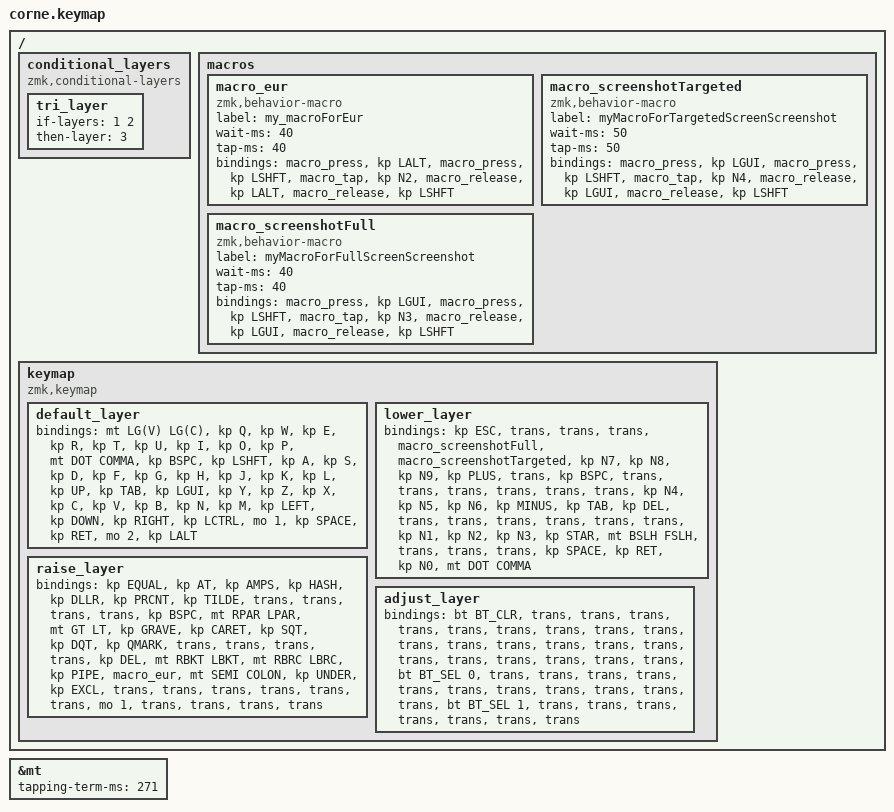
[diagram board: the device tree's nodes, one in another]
/*
 * Copyright (c) 2020 The ZMK Contributors
 *
 * SPDX-License-Identifier: MIT
 */

#include <behaviors.dtsi>
#include <dt-bindings/zmk/keys.h>
#include <dt-bindings/zmk/bt.h>


&mt {
    tapping-term-ms = <271>;
};


/ {

conditional_layers {
        compatible = "zmk,conditional-layers";
        tri_layer {
            if-layers = <1 2>;
            then-layer = <3>;
        };
  };


  macros {
    macro_eur: macro_eur {
        label = "my_macroForEur";
        compatible = "zmk,behavior-macro";
        #binding-cells = <0>;
        wait-ms = <40>;
        tap-ms = <40>;
        bindings
        = <&macro_press   &kp LALT>
        , <&macro_press   &kp LSHFT>    
        , <&macro_tap     &kp N2>
        , <&macro_release &kp LALT>
        , <&macro_release &kp LSHFT>
        ;
    };

  macro_screenshotTargeted: macro_screenshotTargeted {
        label = "myMacroForTargetedScreenScreenshot";
        compatible = "zmk,behavior-macro";
        #binding-cells = <0>;
        wait-ms = <50>;
        tap-ms = <50>;
        bindings
        = <&macro_press   &kp LGUI>
        , <&macro_press   &kp LSHFT>
        , <&macro_tap     &kp N4>
        , <&macro_release &kp LGUI>
        , <&macro_release &kp LSHFT>
        ;
    };


  macro_screenshotFull: macro_screenshotFull {
        label = "myMacroForFullScreenScreenshot";
        compatible = "zmk,behavior-macro";
        #binding-cells = <0>;
        wait-ms = <40>;
        tap-ms = <40>;
        bindings
        = <&macro_press   &kp LGUI>
        , <&macro_press   &kp LSHFT>
        , <&macro_tap     &kp N3>
        , <&macro_release &kp LGUI>
        , <&macro_release &kp LSHFT>
        ;
    };
};



        keymap {
                compatible = "zmk,keymap";

                default_layer {
 bindings = <
&mt LG(V) LG(C) &kp Q &kp W &kp E &kp R &kp T &kp U &kp I &kp O &kp P &mt DOT COMMA &kp BSPC &kp LSHFT &kp A &kp S &kp D &kp F &kp G &kp H &kp J &kp K &kp L &kp UP &kp TAB &kp LGUI &kp Y &kp Z &kp X &kp C &kp V &kp B &kp N &kp M &kp LEFT &kp DOWN &kp RIGHT &kp LCTRL &mo 1 &kp SPACE &kp RET &mo 2 &kp LALT
>;
                };
                lower_layer {

                        bindings = <
&kp ESC &trans &trans &trans &macro_screenshotFull &macro_screenshotTargeted &kp N7 &kp N8 &kp N9 &kp PLUS &trans &kp BSPC &trans &trans &trans &trans &trans &trans &kp N4 &kp N5 &kp N6 &kp MINUS &kp TAB &kp DEL &trans &trans &trans &trans &trans &trans &kp N1 &kp N2 &kp N3 &kp STAR &mt BSLH FSLH &trans &trans &trans &kp SPACE &kp RET &kp N0 &mt DOT COMMA
>;
                };
                raise_layer {

                        bindings = <
&kp EQUAL &kp AT &kp AMPS &kp HASH &kp DLLR &kp PRCNT &kp TILDE &trans &trans &trans &trans &kp BSPC &mt RPAR LPAR &mt GT LT &kp GRAVE &kp CARET &kp SQT &kp DQT &kp QMARK &trans &trans &trans &trans &kp DEL &mt RBKT LBKT &mt RBRC LBRC &kp PIPE &macro_eur &mt SEMI COLON &kp UNDER &kp EXCL &trans &trans &trans &trans &trans &trans &mo 1 &trans &trans &trans &trans
>;
                };
                adjust_layer {
                
                        bindings = <                 
&bt BT_CLR &trans &trans &trans &trans &trans &trans &trans &trans &trans &trans &trans &trans &trans &trans &trans &trans &trans &trans &trans &trans &trans &bt BT_SEL 0 &trans &trans &trans &trans &trans &trans &trans &trans &trans &trans &trans &bt BT_SEL 1 &trans &trans &trans &trans &trans &trans &trans
                       >;
                };
        };
};
